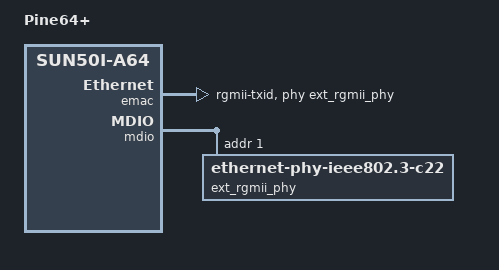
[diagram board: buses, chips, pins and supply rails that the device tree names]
/*
 * Copyright (c) 2016 ARM Ltd.
 *
 * This file is dual-licensed: you can use it either under the terms
 * of the GPL or the X11 license, at your option. Note that this dual
 * licensing only applies to this file, and not this project as a
 * whole.
 *
 *  a) This library is free software; you can redistribute it and/or
 *     modify it under the terms of the GNU General Public License as
 *     published by the Free Software Foundation; either version 2 of the
 *     License, or (at your option) any later version.
 *
 *     This library is distributed in the hope that it will be useful,
 *     but WITHOUT ANY WARRANTY; without even the implied warranty of
 *     MERCHANTABILITY or FITNESS FOR A PARTICULAR PURPOSE.  See the
 *     GNU General Public License for more details.
 *
 * Or, alternatively,
 *
 *  b) Permission is hereby granted, free of charge, to any person
 *     obtaining a copy of this software and associated documentation
 *     files (the "Software"), to deal in the Software without
 *     restriction, including without limitation the rights to use,
 *     copy, modify, merge, publish, distribute, sublicense, and/or
 *     sell copies of the Software, and to permit persons to whom the
 *     Software is furnished to do so, subject to the following
 *     conditions:
 *
 *     The above copyright notice and this permission notice shall be
 *     included in all copies or substantial portions of the Software.
 *
 *     THE SOFTWARE IS PROVIDED "AS IS", WITHOUT WARRANTY OF ANY KIND,
 *     EXPRESS OR IMPLIED, INCLUDING BUT NOT LIMITED TO THE WARRANTIES
 *     OF MERCHANTABILITY, FITNESS FOR A PARTICULAR PURPOSE AND
 *     NONINFRINGEMENT. IN NO EVENT SHALL THE AUTHORS OR COPYRIGHT
 *     HOLDERS BE LIABLE FOR ANY CLAIM, DAMAGES OR OTHER LIABILITY,
 *     WHETHER IN AN ACTION OF CONTRACT, TORT OR OTHERWISE, ARISING
 *     FROM, OUT OF OR IN CONNECTION WITH THE SOFTWARE OR THE USE OR
 *     OTHER DEALINGS IN THE SOFTWARE.
 */

#include "sun50i-a64-pine64.dts"

/ {
	model = "Pine64+";
	compatible = "pine64,pine64-plus", "allwinner,sun50i-a64";

	/* TODO: Camera, touchscreen, etc. */
};

&emac {
	pinctrl-names = "default";
	pinctrl-0 = <&rgmii_pins>;
	phy-mode = "rgmii-txid";
	phy-handle = <&ext_rgmii_phy>;
	status = "okay";
};

&mdio {
	ext_rgmii_phy: ethernet-phy@1 {
		compatible = "ethernet-phy-ieee802.3-c22";
		reg = <1>;
	};
};

&reg_dc1sw {
	/*
	 * Ethernet PHY needs 30ms to properly power up and some more
	 * to initialize. 100ms should be plenty of time to finish
	 * whole process.
	 */
	regulator-enable-ramp-delay = <100000>;
};
